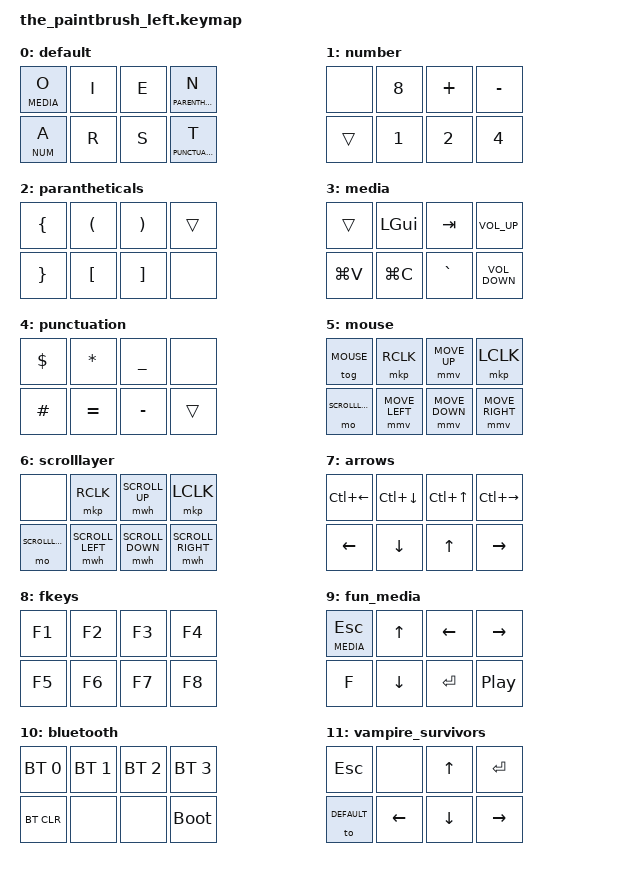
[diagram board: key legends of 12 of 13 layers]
/*
 * Copyright (c) 2021 Mike "KemoNine" Crosson
 *
 * SPDX-License-Identifier: MIT
 */

#include <behaviors.dtsi>
#include <dt-bindings/zmk/keys.h>
#include <dt-bindings/zmk/bt.h>
#include <dt-bindings/zmk/mouse.h>
#include <dt-bindings/zmk/outputs.h>


#define DEFAULT        0
#define NUM            1
#define PARENTHETICALS 2
#define MEDIA          3
#define PUNCTUATION    4
#define MOUSE          5
#define SCROLLLAYER    6
#define ARROW          7
#define FKEYS          8
#define FUNTIME        9
#define BLUETOOTH      10
#define VAMPIRE        11
#define LAYERS         12

// Left/Right
#define ARTSEY_LEFT 1

// OIEN Row
#define KEY_N 3
#define KEY_E 2
#define KEY_I 1
#define KEY_O 0
// ARST Row
#define KEY_T 7
#define KEY_S 6
#define KEY_R 5
#define KEY_A 4

#define KEY_1 5
#define KEY_2 6
#define KEY_4 7
#define KEY_8 1


&mt {
    flavor = "tap-preferred";
    tapping_term_ms = <175>;
    quick-tap-ms = <175>;
};



 / { 
 
 
 
 
    combos {
        compatible = "zmk,combos";



        combo_return_to_base {
            timeout-ms = <50>;
            key-positions = <KEY_O KEY_I KEY_E KEY_N KEY_A KEY_R KEY_S KEY_T>;
            bindings = <&to DEFAULT>;
        };
		
        combo_to_layer_select {
            timeout-ms = <50>;
            key-positions = <KEY_I KEY_E KEY_N KEY_R KEY_S KEY_T>;
            bindings = <&to LAYERS>;
        };
		
        combo_space {
            timeout-ms = <50>;
            key-positions = <KEY_A KEY_R KEY_S KEY_T>;
			layers = <DEFAULT>;
            bindings = <&kp SPC>;
        };
		
        combo_f {
            timeout-ms = <50>;
            key-positions = <KEY_E KEY_N>;
			layers = <DEFAULT>;
            bindings = <&kp F>;
        };
		
        combo_g {
            timeout-ms = <50>;
            key-positions = <KEY_I KEY_E>;
			layers = <DEFAULT>;
            bindings = <&kp G>;
        };
		
        combo_j {
            timeout-ms = <50>;
            key-positions = <KEY_O KEY_I>;
			layers = <DEFAULT>;
            bindings = <&kp J>;
        };
		
        combo_y {
            timeout-ms = <50>;
            key-positions = <KEY_I KEY_N>;
			layers = <DEFAULT>;
            bindings = <&kp Y>;
        };
		
        combo_v {
            timeout-ms = <50>;
            key-positions = <KEY_O KEY_E>;
			layers = <DEFAULT>;
            bindings = <&kp V>;
        };
		
        combo_w {
            timeout-ms = <50>;
            key-positions = <KEY_O KEY_N>;
			layers = <DEFAULT>;
            bindings = <&kp W>;
        };
		
        combo_d {
            timeout-ms = <50>;
            key-positions = <KEY_I KEY_E KEY_N>;
			layers = <DEFAULT>;
            bindings = <&kp D>;
        };
		
        combo_x {
            timeout-ms = <50>;
            key-positions = <KEY_O KEY_I KEY_E>;
			layers = <DEFAULT>;
            bindings = <&kp X>;
        };
		
        combo_q {
            timeout-ms = <50>;
            key-positions = <KEY_O KEY_I KEY_N>;
			layers = <DEFAULT>;
            bindings = <&kp Q>;
        };
		
        combo_z {
            timeout-ms = <50>;
            key-positions = <KEY_O KEY_I KEY_E KEY_N>;
			layers = <DEFAULT>;
            bindings = <&kp Z>;
        };
		
        combo_c {
            timeout-ms = <50>;
            key-positions = <KEY_S KEY_T>;
			layers = <DEFAULT>;
            bindings = <&kp C>;
        };
		
        combo_u {
            timeout-ms = <50>;
            key-positions = <KEY_R KEY_S>;
			layers = <DEFAULT>;
            bindings = <&kp U>;
        };
		
        combo_h {
            timeout-ms = <50>;
            key-positions = <KEY_R KEY_T>;
			layers = <DEFAULT>;
            bindings = <&kp H>;
        };
		
        combo_k {
            timeout-ms = <50>;
            key-positions = <KEY_A KEY_S>;
			layers = <DEFAULT>;
            bindings = <&kp K>;
        };
		
        combo_b {
            timeout-ms = <50>;
            key-positions = <KEY_A KEY_T>;
			layers = <DEFAULT>;
            bindings = <&kp B>;
        };
		
        combo_l {
            timeout-ms = <50>;
            key-positions = <KEY_R KEY_S KEY_T>;
			layers = <DEFAULT>;
            bindings = <&kp L>;
        };
		
        combo_m {
            timeout-ms = <50>;
            key-positions = <KEY_A KEY_R KEY_S>;
			layers = <DEFAULT>;
            bindings = <&kp M>;
        };
		
        combo_p {
            timeout-ms = <50>;
            key-positions = <KEY_A KEY_R KEY_T>;
			layers = <DEFAULT>;
            bindings = <&kp P>;
        };
		
		
		
		
		
        combo_comma {
            timeout-ms = <50>;
            key-positions = <KEY_N KEY_S>;
			layers = <DEFAULT>;
            bindings = <&kp COMMA>;
        };
		
        combo_period {
            timeout-ms = <50>;
            key-positions = <KEY_N KEY_R>;
			layers = <DEFAULT>;
            bindings = <&kp PERIOD>;
        };
		
        combo_slash {
            timeout-ms = <50>;
            key-positions = <KEY_N KEY_A>;
			layers = <DEFAULT>;
            bindings = <&kp SLASH>;
        };
		
        combo_single_quote {
            timeout-ms = <50>;
            key-positions = <KEY_N KEY_R KEY_T>;
			layers = <DEFAULT>;
            bindings = <&kp SINGLE_QUOTE>;
        };
		
        combo_ESC {
            timeout-ms = <50>;
            key-positions = <KEY_E KEY_N KEY_A>;
			layers = <DEFAULT>;
            bindings = <&kp ESC>;
        };
		
        combo_TAB {
            timeout-ms = <50>;
            key-positions = <KEY_I KEY_E KEY_N KEY_A>;
			layers = <DEFAULT>;
            bindings = <&kp TAB>;
        };
		
        combo_CTRL {
            timeout-ms = <50>;
            key-positions = <KEY_O KEY_T>;
			layers = <DEFAULT>;
            bindings = <&sk LCTRL>;
        };
		
        combo_GUI {
            timeout-ms = <50>;
            key-positions = <KEY_O KEY_S>;
			layers = <DEFAULT>;
            bindings = <&sk LGUI>;
        };
		
        combo_ALT {
            timeout-ms = <50>;
            key-positions = <KEY_O KEY_R>;
			layers = <DEFAULT>;
            bindings = <&sk LALT>;
        };
	
        combo_semicolon {
            timeout-ms = <50>;
            key-positions = <KEY_I KEY_A>;
			layers = <DEFAULT>;
            bindings = <&kp SEMICOLON>;
        };
		
        combo_colon {
            timeout-ms = <50>;
            key-positions = <KEY_E KEY_A>;
			layers = <DEFAULT>;
            bindings = <&kp COLON>;
        };
		
        combo_question {
            timeout-ms = <50>;
            key-positions = <KEY_I KEY_N KEY_A>;
			layers = <DEFAULT>;
            bindings = <&kp QUESTION>;
        };
		
        combo_double_quote {
            timeout-ms = <50>;
            key-positions = <KEY_N KEY_A KEY_R>;
			layers = <DEFAULT>;
            bindings = <&kp DOUBLE_QUOTES>;
        };
		
        combo_EXCLAMATION {
            timeout-ms = <50>;
            key-positions = <KEY_I KEY_S>;
			layers = <DEFAULT>;
            bindings = <&kp EXCLAMATION>;
        };
		
        combo_ENTER {
            timeout-ms = <50>;
            key-positions = <KEY_N KEY_T>;
			layers = <DEFAULT>;
            bindings = <&kp ENTER>;
        };
		
        combo_DELETE{
            timeout-ms = <50>;
            key-positions = <KEY_E KEY_R>;
			layers = <DEFAULT>;
            bindings = <&kp ENTER>;
        };
		
        combo_SHIFT {
            timeout-ms = <50>;
            key-positions = <KEY_I KEY_R>;
			layers = <DEFAULT>;
            bindings = <&sk LSHIFT>;
        };
		
        combo_LOCK_SHIFT {
            timeout-ms = <50>;
            key-positions = <KEY_O KEY_I KEY_E KEY_T>;
			layers = <DEFAULT>;
            bindings = <&kt LSHIFT>;
        };
		
        combo_BACKSPACE {
            timeout-ms = <50>;
            key-positions = <KEY_E KEY_S>;
			layers = <DEFAULT>;
            bindings = <&kp BSPC>;
        };
		
        combo_BACKSPACE_TWO {
            timeout-ms = <50>;
            key-positions = <KEY_E KEY_T>;
			layers = <DEFAULT>;
            bindings = <&kp BSPC>;
        };
		
		
        combo_Umlaute {
            timeout-ms = <50>;
            key-positions = <KEY_O KEY_A>;
			layers = <DEFAULT>;
            bindings = <&kp LA(U)>;
        };
		
		
        combo_Play_Pause1 {
            timeout-ms = <50>;
            key-positions = <KEY_N KEY_A KEY_R KEY_S>;
			layers = <DEFAULT>;
            bindings = <&kp C_PLAY_PAUSE>;
        };
		
		
		
		
        combo_zero {
            timeout-ms = <50>;
            key-positions = <KEY_8 KEY_2>;
			layers = <NUM>;
            bindings = <&kp N0>;
        };
		
        combo_three {
            timeout-ms = <50>;
            key-positions = <KEY_1 KEY_2>;
			layers = <NUM>;
            bindings = <&kp N3>;
        };
	
	combo_five {
            timeout-ms = <50>;
            key-positions = <KEY_1 KEY_4>;
			layers = <NUM>;
            bindings = <&kp N5>;
	};

		
        combo_six {
            timeout-ms = <50>;
            key-positions = <KEY_2 KEY_4>;
			layers = <NUM>;
            bindings = <&kp N6>;
        };
		
        combo_seven {
            timeout-ms = <50>;
            key-positions = <KEY_1 KEY_2 KEY_4>;
			layers = <NUM>;
            bindings = <&kp N7>;
        };
		
        combo_nine {
            timeout-ms = <50>;
            key-positions = <KEY_8 KEY_1>;
			layers = <NUM>;
            bindings = <&kp N9>;
        };
		
		
        combo_numeuro {
            timeout-ms = <50>;
            key-positions = <KEY_E KEY_N>;
			layers = <NUM>;
            bindings = <&kp LS(LA(2))>;
        };
		
		
		
		
        combo_less {
            timeout-ms = <50>;
            key-positions = <KEY_O KEY_I>;
			layers = <PARENTHETICALS>;
            bindings = <&kp LESS_THAN>;
        };
		
        combo_greater {
            timeout-ms = <50>;
            key-positions = <KEY_I KEY_E>;
			layers = <PARENTHETICALS>;
            bindings = <&kp GREATER_THAN>;
        };
		
        combo_tilda {
            timeout-ms = <50>;
            key-positions = <KEY_A KEY_R>;
			layers = <PARENTHETICALS>;
            bindings = <&kp TILDE>;
        };
		
        combo_circ {
            timeout-ms = <50>;
            key-positions = <KEY_R KEY_S>;
			layers = <PARENTHETICALS>;
            bindings = <&kp CARET>;
        };
		
        combo_grave {
            timeout-ms = <50>;
            key-positions = <KEY_A KEY_R KEY_S>;
			layers = <PARENTHETICALS>;
            bindings = <&kp GRAVE>;
        };
		
		
		
		
        combo_new_tab {
            timeout-ms = <50>;
            key-positions = <KEY_I KEY_R>;
			layers = <MEDIA>;
            bindings = <&kp LG(T)>;
        };
		
        combo_cmd_new {
            timeout-ms = <50>;
            key-positions = <KEY_E KEY_S>;
			layers = <MEDIA>;
            bindings = <&kp LG(N)>;
        };
		
        combo_close {
            timeout-ms = <50>;
            key-positions = <KEY_N KEY_T>;
			layers = <MEDIA>;
            bindings = <&kp LG(W)>;
        };
		
   
        combo_reload {
            timeout-ms = <50>;
            key-positions = <KEY_I KEY_E KEY_N>;
			layers = <MEDIA>;
            bindings = <&kp LG(R)>;
        };
		
        combo_cmd_z {
            timeout-ms = <50>;
            key-positions = <KEY_R KEY_S>;
			layers = <MEDIA>;
            bindings = <&kp LG(Z)>;
        };
		
        combo_cmd_shft_z {
            timeout-ms = <50>;
            key-positions = <KEY_R KEY_S>;
			layers = <MEDIA>;
            bindings = <&kp LG(LS(Z))>;
        };
		
		
		
			
        combo_at {
            timeout-ms = <50>;
            key-positions = <KEY_O KEY_I>;
			layers = <PUNCTUATION>;
            bindings = <&kp AT >;
        };
			
        combo_backslash {
            timeout-ms = <50>;
            key-positions = <KEY_I KEY_E>;
			layers = <PUNCTUATION>;
            bindings = <&kp BACKSLASH>;
        };
			
        combo_percent {
            timeout-ms = <50>;
            key-positions = <KEY_A KEY_R KEY_S>;
			layers = <PUNCTUATION>;
            bindings = <&kp PERCENT>;
        };
			
        combo_pipe {
            timeout-ms = <50>;
            key-positions = <KEY_A KEY_R>;
			layers = <PUNCTUATION>;
            bindings = <&kp PIPE>;
        };
			
        combo_ampersand {
            timeout-ms = <50>;
            key-positions = <KEY_R KEY_S>;
			layers = <PUNCTUATION>;
            bindings = <&kp AMPERSAND>;
        };
			
				
			
			
        combo_toggle_mouse {
            timeout-ms = <50>;
            key-positions = <KEY_I KEY_N KEY_S>;
			layers = <DEFAULT MOUSE>;
            bindings = <&tog MOUSE>;
        };
			
			
			
        combo_middle_click {
            timeout-ms = <50>;
            key-positions = <KEY_I KEY_N>;
			layers = <MOUSE SCROLLLAYER>;
            bindings = <&mkp MCLK>;
        };
		
		
			
        combo_toggle_arrows {
            timeout-ms = <50>;
            key-positions = <KEY_E KEY_R KEY_T>;
			layers = <DEFAULT ARROW>;
            bindings = <&tog ARROW>;
        };	
		
		
			
        combo_arrow_backspace {
            timeout-ms = <50>;
            key-positions = <KEY_N KEY_T>;
			layers = <ARROW>;
            bindings = <&kp BSPC>;
        };	
		
        combo_arrow_enter {
            timeout-ms = <50>;
            key-positions = <KEY_E KEY_S>;
			layers = <ARROW>;
            bindings = <&kp ENTER>;
        };	
		
		

			
        combo_one_shotF {
            timeout-ms = <50>;
            key-positions = <KEY_E KEY_N KEY_S KEY_T>;
			layers = <DEFAULT>;
            bindings = <&sl FKEYS>;
        };
		
		
		
        combo_F9 {
            timeout-ms = <50>;
            key-positions = <KEY_O KEY_A>;
			layers = <FKEYS>;
            bindings = <&kp F9>;
        };		
		
		
        combo_F10 {
            timeout-ms = <50>;
            key-positions = <KEY_I KEY_R>;
			layers = <FKEYS>;
            bindings = <&kp F10>;
        };		
		
        combo_F11 {
            timeout-ms = <50>;
            key-positions = <KEY_E KEY_S>;
			layers = <FKEYS>;
            bindings = <&kp F11>;
        };		
		
        combo_F12 {
            timeout-ms = <50>;
            key-positions = <KEY_N KEY_T>;
			layers = <FKEYS>;
            bindings = <&kp F12>;
        };	
		
		
		combo_toggle_fun_layer {
            timeout-ms = <50>;
            key-positions = <KEY_O KEY_I KEY_A KEY_R>;
			layers = <DEFAULT FUNTIME>;
            bindings = <&tog FUNTIME>;
		};
		
		combo_fun_next_tab {
            timeout-ms = <50>;
            key-positions = <KEY_N KEY_T>;
			layers = <FUNTIME>;
            bindings = <&kp LC(TAB)>;
		};
		
		combo_fun_last_tab {
            timeout-ms = <50>;
            key-positions = <KEY_E KEY_S>;
			layers = <FUNTIME>;
            bindings = <&kp LS(LC(TAB))>;
		};
		
		combo_fun_close_tab {
            timeout-ms = <50>;
            key-positions = <KEY_I KEY_R>;
			layers = <FUNTIME>;
            bindings = <&kp LG(W)>;
		};
		
		combo_fun_toggle_out {
            timeout-ms = <50>;
            key-positions = <KEY_O KEY_A>;
			layers = <FUNTIME>;
            bindings = <&tog FUNTIME>;
		};
		
		
		
		
		
		combo_toggle_bluetooth_layer {
            timeout-ms = <50>;
            key-positions = <KEY_O KEY_I KEY_E KEY_A KEY_R KEY_S>;
			layers = <DEFAULT BLUETOOTH>;
            bindings = <&tog BLUETOOTH>;
		};
		
		
    };
	
	
    keymap {
        compatible = "zmk,keymap";

		default {
		                          bindings = <                                 
		     &lt MEDIA O &kp I  &kp E   &lt PARENTHETICALS N    
		     &lt NUM A   &kp R  &kp S   &lt PUNCTUATION T            
		                           >;
					
        };
		
		

		number {
		                          bindings = <          
		     &none        &kp N8 &kp PLUS &kp MINUS          
		     &trans       &kp N1 &kp N2   &kp N4          
		                           >;
					
        };
		
		
		parantheticals {
		                          bindings = <                                 
		     &kp LEFT_BRACE  &kp LPAR          &kp RPAR             &trans
		     &kp RIGHT_BRACE &kp LEFT_BRACKET  &kp RIGHT_BRACKET    &none
		                           >;
					
        };
		
		
		media {
		                          bindings = <                                 
		     &trans    &kp LGUI        &kp TAB        &kp C_VOL_UP
		     &kp LG(V) &kp LG(C)       &kp GRAVE      &kp C_VOLUME_DOWN
		                           >;
					
        };
		
		
		punctuation {
		                          bindings = <                                 
		     &kp DOLLAR &kp ASTERISK  &kp UNDERSCORE &none    
		     &kp HASH   &kp EQUAL     &kp MINUS      &trans
		                           >;
					
        };
		
		
		
		mouse {
				                          bindings = <                                 
		     &tog MOUSE      &mkp RCLK      &mmv MOVE_UP   &mkp LCLK 
             &mo SCROLLLAYER &mmv MOVE_LEFT &mmv MOVE_DOWN &mmv MOVE_RIGHT
				                           >;
					
		        };
		
		scrolllayer {
				                          bindings = <                                 
				     &none            &mkp RCLK        &mwh SCROLL_UP   &mkp LCLK
				     &mo SCROLLLAYER  &mwh SCROLL_LEFT &mwh SCROLL_DOWN &mwh SCROLL_RIGHT
				                           >;
					
		        };
				
				
				
		arrows {
				                          bindings = <                                 
				     &kp LC(LEFT)  &kp LC(DOWN)   &kp LC(UP)     &kp LC(RIGHT)
				     &kp LEFT      &kp DOWN       &kp UP         &kp RIGHT
				                           >;
					
		        };
		
		fkeys {
				                          bindings = <                                 
				     &kp F1   &kp F2    &kp F3      &kp F4
				     &kp F5   &kp F6    &kp F7      &kp F8
				                           >;
					
		        };
		
		
		fun_media {
				                          bindings = <                                 
				     &lt MEDIA ESC  &kp UP    &kp LEFT    &kp RIGHT
				     &kp F    &kp DOWN  &kp RET     &kp C_PLAY_PAUSE
				                           >;
					
		        };
			
		bluetooth {
				                          bindings = <                                 
				     &bt BT_SEL 0 &bt BT_SEL 1 &bt BT_SEL 2 &bt BT_SEL 3
				     &bt BT_CLR   &none        &none        &bootloader
				                           >;
					
		        };
				
		vampire_survivors {
				                          bindings = <                                 
				     &kp ESC     &none     &kp UP      &kp ENTER
				     &to DEFAULT &kp LEFT  &kp DOWN    &kp RIGHT
				                           >;
					
		        };
		
		layer_select {
				                          bindings = <                                 
				     &to DEFAULT &to FUNTIME &none   &kp ENTER
				     &to DEFAULT &to VAMPIRE &none   &kp RIGHT
				                           >;
					
		        };
		
		
		
    };
};
